# STM32MP13xx register map
File version: 1.7
CPU: CA7 r0p0, little endian, MPU, FPU, 4 interrupt priority bits
Registers are 32-bit, read-write, reset 0x0 unless marked. A register's access mark holds for its fields unless they carry their own. Offsets are from the block's base; [hi:lo] are bit positions; {n}, {i} and the like mark numbered series; 'fields as' and 'values as' point back to an identical list.

## AXIMC
Base 0x57000000
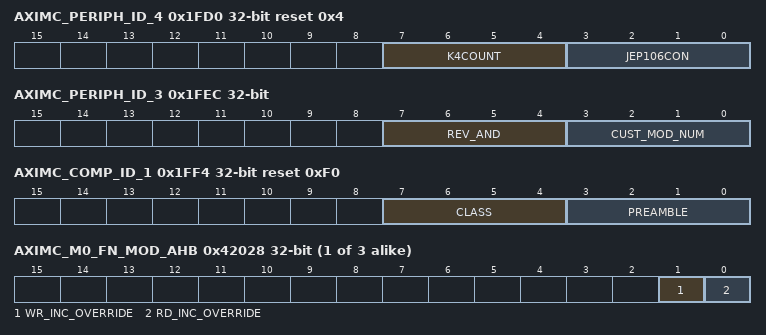
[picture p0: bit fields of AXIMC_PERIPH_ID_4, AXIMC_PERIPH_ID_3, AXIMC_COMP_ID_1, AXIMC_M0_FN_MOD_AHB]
0x1FD0 AXIMC_PERIPH_ID_4 ro reset 0x4 — AXIMC peripheral ID4 register
  [7:4] K4COUNT — register file size
  [3:0] JEP106CON — JEP106 continuation code
{0x1FC0+4i} AXIMC_PERIPH_ID_{i} ro (i=5..7) — AXIMC peripheral ID{i} register
  [7:0] PERIPH_ID_{i} — reserved, not used.
0x1FE0 AXIMC_PERIPH_ID_0 ro — AXIMC peripheral ID0 register
  [7:0] PERIPH_ID_0 — part number [7:0]
0x1FE4 AXIMC_PERIPH_ID_1 ro reset 0xB4 — AXIMC peripheral ID1 register
  [7:0] PERIPH_ID_1 — JEP106 identity [3:0], part number [11:8]
0x1FE8 AXIMC_PERIPH_ID_2 ro reset 0x3B — AXIMC peripheral ID2 register
  [7:0] PERIPH_ID_2 — part revision, JEP106 code flag, JEP106 identity [6:4]
0x1FEC AXIMC_PERIPH_ID_3 ro — AXIMC peripheral ID3 register
  [7:4] REV_AND — customer version
    0=none
  [3:0] CUST_MOD_NUM — customer modification
    0=none
0x1FF0 AXIMC_COMP_ID_0 ro reset 0xD — AXIMC component ID0 register
  [7:0] PREAMBLE — preamble bits [7:0]
0x1FF4 AXIMC_COMP_ID_1 ro reset 0xF0 — AXIMC component ID1 register
  [7:4] CLASS — Component class
    15=generic IP component class
  [3:0] PREAMBLE — preamble bits [11:8]
    0=common ID value
0x1FF8 AXIMC_COMP_ID_2 ro reset 0x5 — AXIMC component ID2 register
  [7:0] PREAMBLE — preamble bits [19:12]
0x1FFC AXIMC_COMP_ID_3 ro reset 0xB1 — AXIMC component ID3 register
  [7:0] PREAMBLE — preamble bits [27:20]
{0x42024+0x1000*i} AXIMC_M{i}_FN_MOD2 (i=0..2) — AXIMC master {i} packing functionality register
  [0] BYPASS_MERGE — Disable packing of beats to match the output data width Unaligned transactions are not realigned to the input data word boundary.
    0=normal operation; 1=disable packing
{0x42028+0x1000*i} AXIMC_M{i}_FN_MOD_AHB (i=0..2) — AXIMC master {i} AHB conversion override functionality register
  [1] WR_INC_OVERRIDE — Converts all AHB-Lite read transactions to a series of single beat AXI transactions
    0=override disabled; 1=override enabled
  [0] RD_INC_OVERRIDE — Converts all AHB-Lite write transactions to a series of single beat AXI transactions, and each AHB-Lite write beat is acknowledged with the AXI buffered write response.
    0=override disabled; 1=override enabled
{0x42100+0x1000*i} AXIMC_M{i}_READ_QOS reset 0x6 (i=0..2) — AXIMC master {i} read priority register
  [3:0] AR_QOS — read channel QoS setting
    0=lowest priority; 15=highest priority
{0x42104+0x1000*i} AXIMC_M{i}_WRITE_QOS reset 0x6 (i=0..2) — AXIMC master {i} write priority register
  [3:0] AW_QOS — write channel QoS setting
    0=lowest priority; 15=highest priority
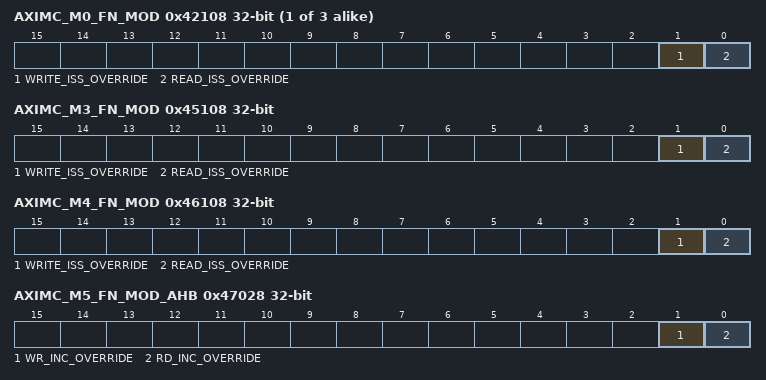
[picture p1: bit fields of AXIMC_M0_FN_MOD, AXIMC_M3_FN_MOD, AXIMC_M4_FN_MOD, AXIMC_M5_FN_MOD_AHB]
{0x42108+0x1000*i} AXIMC_M{i}_FN_MOD (i=0..2) — AXIMC master {i} issuing capability override functionality register
  [1] WRITE_ISS_OVERRIDE — override AMIB write issuing capability
    0=normal issuing capability; 1=force issuing capability to 1
  [0] READ_ISS_OVERRIDE — override AMIB read issuing capability
    0=normal issuing capability; 1=force issuing capability to 1
0x45100 AXIMC_M3_READ_QOS reset 0x7 — AXIMC master 3 read priority register
  fields as AXIMC_M0_READ_QOS
0x45104 AXIMC_M3_WRITE_QOS reset 0x7 — AXIMC master 3 write priority register
  fields as AXIMC_M0_WRITE_QOS
0x45108 AXIMC_M3_FN_MOD — AXIMC master 3 packing functionality register
  fields as AXIMC_M0_FN_MOD
0x4602C AXIMC_M4_FN_MOD_LB — AXIMC long burst capability inhibition register
  [0] FN_MOD_LB — controls burst breaking of long bursts
    0=long bursts can not be generated at the output of the ASIB; 1=long bursts can be generated at the output of the ASIB
0x46100 AXIMC_M4_READ_QOS reset 0x7 — AXIMC master 4 read priority register
  fields as AXIMC_M0_READ_QOS
0x46104 AXIMC_M4_WRITE_QOS reset 0x7 — AXIMC master 4 write priority register
  fields as AXIMC_M0_WRITE_QOS
0x46108 AXIMC_M4_FN_MOD — AXIMC master 4 packing functionality register
  fields as AXIMC_M0_FN_MOD
0x47024 AXIMC_M5_FN_MOD2 — AXIMC master 5 packing functionality register
  fields as AXIMC_M0_FN_MOD2
0x47028 AXIMC_M5_FN_MOD_AHB — AXIMC master 5 AHB conversion override functionality register
  [1] WR_INC_OVERRIDE — converts all AHB-Lite read transactions to a series of single beat AXI transactions
    0=override disabled; 1=override enabled
  [0] RD_INC_OVERRIDE — converts all AHB-Lite write transactions to a series of single beat AXI transactions, and each AHB-Lite write beat is acknowledged with the AXI buffered write response.
    0=override disabled; 1=override enabled
0x47100 AXIMC_M5_READ_QOS reset 0x4 — AXIMC master 5 read priority register
  fields as AXIMC_M0_READ_QOS
0x47104 AXIMC_M5_WRITE_QOS reset 0x4 — AXIMC master 5 write priority register
  fields as AXIMC_M0_WRITE_QOS
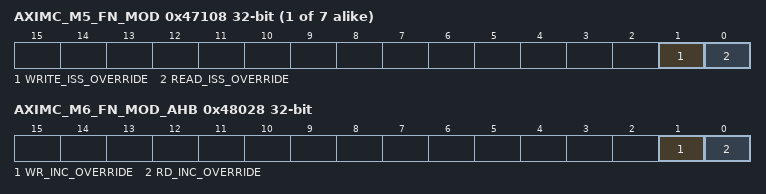
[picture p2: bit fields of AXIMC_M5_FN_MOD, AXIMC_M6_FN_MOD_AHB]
{0x42108+0x1000*i} AXIMC_M{i}_FN_MOD (i=5..11) — AXIMC master {i} issuing capability override functionality register
  fields as AXIMC_M0_FN_MOD
0x48024 AXIMC_M6_FN_MOD2 — AXIMC master 6 packing functionality register
  fields as AXIMC_M0_FN_MOD2
0x48028 AXIMC_M6_FN_MOD_AHB — AXIMC master 6 AHB conversion override functionality register
  fields as AXIMC_M5_FN_MOD_AHB
0x48100 AXIMC_M6_READ_QOS reset 0x4 — AXIMC master 6 read priority register
  fields as AXIMC_M0_READ_QOS
0x48104 AXIMC_M6_WRITE_QOS reset 0x4 — AXIMC master 6 write priority register
  fields as AXIMC_M0_WRITE_QOS
0x49100 AXIMC_M7_READ_QOS reset 0x8 — AXIMC master 7 read priority register
  fields as AXIMC_M0_READ_QOS
0x49104 AXIMC_M7_WRITE_QOS reset 0x8 — AXIMC master 7 write priority register
  fields as AXIMC_M0_WRITE_QOS
0x4A100 AXIMC_M8_READ_QOS reset 0x8 — AXIMC master 8 read priority register
  fields as AXIMC_M0_READ_QOS
0x4A104 AXIMC_M8_WRITE_QOS reset 0x8 — AXIMC master 8 write priority register
  fields as AXIMC_M0_WRITE_QOS
{0x42100+0x1000*i} AXIMC_M{i}_READ_QOS reset 0x2 (i=9..11) — AXIMC master {i} read priority register
  fields as AXIMC_M0_READ_QOS
{0x42104+0x1000*i} AXIMC_M{i}_WRITE_QOS reset 0x2 (i=9..11) — AXIMC master {i} write priority register
  fields as AXIMC_M0_WRITE_QOS
